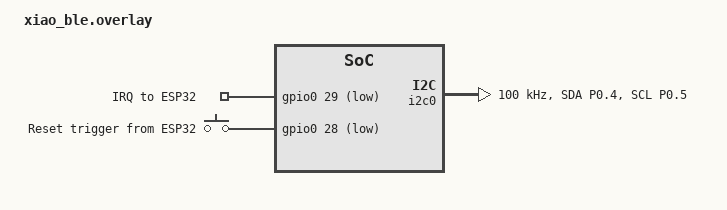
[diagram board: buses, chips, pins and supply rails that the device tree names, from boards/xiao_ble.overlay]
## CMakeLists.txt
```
cmake_minimum_required(VERSION 3.20.0)
find_package(Zephyr REQUIRED HINTS $ENV{ZEPHYR_BASE})
project(xiao_ble)

target_sources(app PRIVATE
    src/main.c
    src/i2c_target.c
    src/event_queue.c
    src/ble_central.c
    src/gatt_client.c
)
```

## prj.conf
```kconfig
# Phase 2: I2C Target + BLE Central (Scanning)

# I2C Target Mode
CONFIG_I2C=y
CONFIG_I2C_TARGET=y
CONFIG_I2C_TARGET_BUFFER_MODE=y

# GPIO (IRQ output + RST input)
CONFIG_GPIO=y

# BLE Central (scanning, future: connections)
CONFIG_BT=y
CONFIG_BT_CENTRAL=y
CONFIG_BT_OBSERVER=y
CONFIG_BT_GATT_CLIENT=y
CONFIG_BT_MAX_CONN=5
CONFIG_BT_MAX_PAIRED=5
CONFIG_BT_DEVICE_NAME="XIAO-BLE-Bridge"

# BLE Security (needed for Phase 3+)
CONFIG_BT_SMP=y
CONFIG_BT_BONDABLE=y
CONFIG_BT_SETTINGS=y
CONFIG_SETTINGS=y
CONFIG_FLASH=y
CONFIG_FLASH_MAP=y
CONFIG_NVS=y

# Persistent auto-reconnect: background connect to bonded bulbs via the
# controller filter accept list (Phase 5).
CONFIG_BT_FILTER_ACCEPT_LIST=y

# Connection timeout (Hue bulbs advertise slowly, need >3s default)
CONFIG_BT_CREATE_CONN_TIMEOUT=10

# Logging
CONFIG_LOG=y
CONFIG_LOG_DEFAULT_LEVEL=3
CONFIG_BT_LOG_LEVEL_WRN=y

# Watchdog (reboot if no PING in 30s)
CONFIG_WATCHDOG=y
CONFIG_WDT_DISABLE_AT_BOOT=n

# System
CONFIG_REBOOT=y
CONFIG_MAIN_STACK_SIZE=4096
```

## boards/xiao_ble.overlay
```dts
/*
 * Device tree overlay for XIAO nRF52840 BLE offload firmware.
 *
 * Pin assignments:
 *   D4 (P0.04) = SDA  (I2C target)
 *   D5 (P0.05) = SCL  (I2C target)
 *   D3 (P0.29) = IRQ  output to ESP32 (active LOW)
 *   D2 (P0.28) = RST  input from ESP32 (falling edge triggers reboot)
 */

/ {
    aliases {
        i2c-target = &i2c0;
    };

    gpio_pins {
        compatible = "gpio-keys";

        irq_pin: irq_pin {
            gpios = <&gpio0 29 GPIO_ACTIVE_LOW>;
            label = "IRQ to ESP32";
        };

        rst_pin: rst_pin {
            gpios = <&gpio0 28 (GPIO_PULL_UP | GPIO_ACTIVE_LOW)>;
            label = "Reset trigger from ESP32";
        };
    };
};

&i2c0 {
    compatible = "nordic,nrf-twis";
    status = "okay";
    pinctrl-0 = <&i2c0_default>;
    pinctrl-names = "default";
    clock-frequency = <I2C_BITRATE_STANDARD>;
};

&pinctrl {
    i2c0_default: i2c0_default {
        group1 {
            psels = <NRF_PSEL(TWIS_SDA, 0, 4)>,
                    <NRF_PSEL(TWIS_SCL, 0, 5)>;
        };
    };
};
```

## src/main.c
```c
/**
 * main.c — XIAO nRF52840 BLE offload firmware (Phase 1: I2C + PING/PONG)
 *
 * Initializes:
 *   - I2C target interface (address 0x08)
 *   - Event queue with IRQ signalling (D3 / P0.29)
 *   - Reset trigger input (D2 / P0.28)
 *   - Software watchdog (reboots if no PING in 30s)
 *
 * Queues a READY event on boot so the ESP32 knows we're alive.
 */

#include <zephyr/kernel.h>
#include <zephyr/drivers/gpio.h>
#include <zephyr/sys/reboot.h>
#include <zephyr/logging/log.h>

#include "i2c_target.h"
#include "event_queue.h"
#include "ble_central.h"

LOG_MODULE_REGISTER(main, LOG_LEVEL_INF);

/* Red LED (P0.26) — used as heartbeat indicator */
#define LED_NODE DT_ALIAS(led0)
static const struct gpio_dt_spec led = GPIO_DT_SPEC_GET(LED_NODE, gpios);

/* Reset input pin — D2 is P0.28 on XIAO nRF52840 */
#define RST_GPIO_NODE DT_NODELABEL(gpio0)
#define RST_PIN       28

/* Watchdog timeout: reboot if no PING for this many seconds */
#define WDT_TIMEOUT_SEC 30

static const struct device *rst_gpio_dev;
static struct gpio_callback rst_cb_data;

/* Reset pin interrupt callback */
static void rst_pin_handler(const struct device *dev,
                            struct gpio_callback *cb,
                            uint32_t pins)
{
    LOG_WRN("Reset triggered by ESP32 via D2");
    k_msleep(5);  /* brief delay for signal stability */
    sys_reboot(SYS_REBOOT_COLD);
}

static int init_reset_pin(void)
{
    rst_gpio_dev = DEVICE_DT_GET(RST_GPIO_NODE);
    if (!device_is_ready(rst_gpio_dev)) {
        LOG_ERR("RST GPIO device not ready");
        return -ENODEV;
    }

    int ret = gpio_pin_configure(rst_gpio_dev, RST_PIN,
                                  GPIO_INPUT | GPIO_PULL_UP);
    if (ret < 0) {
        LOG_ERR("Failed to configure RST pin: %d", ret);
        return ret;
    }

    ret = gpio_pin_interrupt_configure(rst_gpio_dev, RST_PIN,
                                        GPIO_INT_EDGE_TO_ACTIVE);
    if (ret < 0) {
        LOG_ERR("Failed to configure RST interrupt: %d", ret);
        return ret;
    }

    gpio_init_callback(&rst_cb_data, rst_pin_handler, BIT(RST_PIN));
    gpio_add_callback(rst_gpio_dev, &rst_cb_data);

    LOG_INF("Reset pin (D2/P0.%d) ready", RST_PIN);
    return 0;
}

/* Declared in i2c_target.c */
extern bool i2c_target_check_ping(void);

int main(void)
{
    int ret;

    LOG_INF("XIAO BLE offload firmware v%d starting", FIRMWARE_VERSION);

    /* Configure heartbeat LED */
    if (gpio_is_ready_dt(&led)) {
        gpio_pin_configure_dt(&led, GPIO_OUTPUT_ACTIVE);
    }

    /* Initialize event queue (includes IRQ GPIO setup) */
    ret = event_queue_init();
    if (ret < 0) {
        LOG_ERR("Event queue init failed: %d", ret);
        return ret;
    }

    /* Initialize I2C target */
    ret = i2c_target_init();
    if (ret < 0) {
        LOG_ERR("I2C target init failed: %d", ret);
        return ret;
    }

    /* Initialize BLE stack */
    ret = ble_central_init();
    if (ret < 0) {
        LOG_ERR("BLE init failed: %d", ret);
        return ret;
    }

    /* Initialize reset input pin */
    ret = init_reset_pin();
    if (ret < 0) {
        LOG_WRN("Reset pin init failed (non-fatal): %d", ret);
    }

    /* Begin persistent auto-reconnect to all bonded bulbs (Phase 5). Bonds
     * were loaded by ble_central_init(); this arms background connection so
     * bulbs stay reachable without an explicit command. */
    ble_central_autoconnect_start();

    /* Queue READY event — ESP32 will see IRQ go LOW */
    event_queue_push_simple(EVT_READY);
    LOG_INF("READY event queued, waiting for ESP32");

    /*
     * Main loop: software watchdog.
     * If we don't receive a PING within WDT_TIMEOUT_SEC, reboot.
     */
    int64_t last_ping_time = k_uptime_get();

    while (1) {
        k_msleep(1000);  /* check every second */

        /* Toggle LED as heartbeat */
        if (gpio_is_ready_dt(&led)) {
            gpio_pin_toggle_dt(&led);
        }

        if (i2c_target_check_ping()) {
            last_ping_time = k_uptime_get();
            LOG_DBG("PING received, watchdog fed");
        }

        int64_t elapsed_ms = k_uptime_get() - last_ping_time;
        if (elapsed_ms > (WDT_TIMEOUT_SEC * 1000)) {
            LOG_ERR("No PING for %d seconds, rebooting!", WDT_TIMEOUT_SEC);
            sys_reboot(SYS_REBOOT_COLD);
        }
    }

    return 0;
}
```

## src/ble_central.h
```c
#ifndef BLE_CENTRAL_H
#define BLE_CENTRAL_H

#include <stdint.h>
#include <stdbool.h>

/**
 * Initialize the BLE stack (must be called from main thread).
 * Returns 0 on success.
 */
int ble_central_init(void);

/*
 * Scanning
 */

/**
 * Start BLE scanning for the given duration (seconds).
 * Scan results are queued as EVT_SCAN_RESULT events.
 * EVT_SCAN_DONE is queued when duration expires or scan_stop() called.
 * Returns 0 on success.
 */
int ble_central_scan_start(uint8_t duration_sec);

/**
 * Stop an active scan immediately.
 * Queues EVT_SCAN_DONE.
 * Returns 0 on success, -EALREADY if not scanning.
 */
int ble_central_scan_stop(void);

/**
 * Returns true if a scan is currently active.
 */
bool ble_central_is_scanning(void);

/*
 * Connections
 */

/**
 * Connect to a BLE device by address.
 * addr: 6-byte BLE address (little-endian)
 * addr_type: 0 = public, 1 = random
 * Queues EVT_CONNECTED on success, EVT_CMD_ERROR on failure.
 * Returns 0 if connection attempt started.
 */
int ble_central_connect(const uint8_t *addr, uint8_t addr_type);

/**
 * Disconnect a connection by handle.
 * Queues EVT_DISCONNECTED.
 * Returns 0 on success.
 */
int ble_central_disconnect(uint16_t conn_handle);

/**
 * Initiate bonding (pairing + key storage) on a connection.
 * Requires an active connection. Queues EVT_BOND_COMPLETE.
 * Returns 0 if bonding started.
 */
int ble_central_bond(uint16_t conn_handle);

/**
 * Delete the stored bond (LTK) for a peer address.
 * addr: 6-byte BLE address (little-endian)
 * addr_type: 0 = public, 1 = random
 * No connection required; clears the key from settings/NVS.
 * Returns 0 on success (or if no bond existed).
 */
int ble_central_unpair(const uint8_t *addr, uint8_t addr_type);

/**
 * Delete all stored bonds.
 * Returns 0 on success.
 */
int ble_central_unpair_all(void);

/**
 * Get connection handle for an address. Returns -1 if not connected.
 */
int ble_central_get_handle(const uint8_t *addr);

/**
 * Get number of active connections.
 */
uint8_t ble_central_connection_count(void);

/**
 * Re-announce all currently active connections by queuing EVT_CONNECTED for
 * each (plus EVT_ENC_CHANGE for those already encrypted). Lets the ESP32
 * rebuild its view of live links after an independent reboot, since the nRF
 * holds connections across ESP32 restarts.
 */
void ble_central_report_connections(void);

/**
 * Get the bt_conn pointer for a connection handle.
 * Returns NULL if handle is invalid or not connected.
 * Used by gatt_client to issue GATT operations.
 */
struct bt_conn *ble_central_get_conn(uint16_t conn_handle);

/**
 * Map a bt_conn pointer back to our connection handle index.
 * Returns 0xFFFF if not found.
 */
uint16_t ble_central_conn_to_handle(struct bt_conn *conn);

/*
 * Persistent auto-reconnect (Phase 5)
 */

/**
 * Populate the filter accept list from stored bonds and begin background
 * auto-connection to every bonded bulb. Bonded devices are then kept
 * persistently connected (and re-encrypted) without any command from the
 * ESP32, reconnecting automatically whenever they advertise.
 *
 * Call once after ble_central_init(). Safe to call again to refresh the
 * accept list after bonds change. Returns 0 on success.
 */
int ble_central_autoconnect_start(void);

#endif /* BLE_CENTRAL_H */
```

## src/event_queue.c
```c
/**
 * event_queue.c — FIFO event queue with IRQ GPIO signalling.
 *
 * Events are queued by BLE callbacks (or PING handler in Phase 1)
 * and drained by the ESP32 reading REG_EVENT via I2C.
 *
 * IRQ pin (D3 / P0.29): HIGH = idle, LOW = events pending.
 */

#include <zephyr/kernel.h>
#include <zephyr/drivers/gpio.h>
#include <zephyr/logging/log.h>
#include <string.h>

#include "event_queue.h"

LOG_MODULE_REGISTER(event_queue, LOG_LEVEL_INF);

/* IRQ GPIO — D3 is P0.29 on XIAO nRF52840 */
#define IRQ_NODE DT_NODELABEL(gpio0)
#define IRQ_PIN  29

static const struct device *gpio_dev;

/* Circular buffer */
static struct event_entry queue[EVENT_QUEUE_SIZE];
static uint8_t head;  /* next read position */
static uint8_t tail;  /* next write position */
static uint8_t count;

static struct k_spinlock lock;

static void irq_pin_set(bool events_pending)
{
    if (gpio_dev) {
        /* Active LOW: events pending = pin LOW */
        gpio_pin_set(gpio_dev, IRQ_PIN, events_pending ? 0 : 1);
    }
}

int event_queue_init(void)
{
    gpio_dev = DEVICE_DT_GET(IRQ_NODE);
    if (!device_is_ready(gpio_dev)) {
        LOG_ERR("GPIO device not ready");
        return -ENODEV;
    }

    int ret = gpio_pin_configure(gpio_dev, IRQ_PIN,
                                  GPIO_OUTPUT_HIGH);  /* idle = HIGH */
    if (ret < 0) {
        LOG_ERR("Failed to configure IRQ pin: %d", ret);
        return ret;
    }

    head = 0;
    tail = 0;
    count = 0;

    LOG_INF("Event queue initialized (IRQ on P0.%d)", IRQ_PIN);
    return 0;
}

int event_queue_push(uint8_t type, const uint8_t *payload, uint8_t len)
{
    if (len > EVENT_MAX_PAYLOAD) {
        len = EVENT_MAX_PAYLOAD;
    }

    k_spinlock_key_t key = k_spin_lock(&lock);

    if (count >= EVENT_QUEUE_SIZE) {
        k_spin_unlock(&lock, key);
        LOG_WRN("Event queue full, dropping event 0x%02x", type);
        return -ENOMEM;
    }

    struct event_entry *entry = &queue[tail];
    entry->type = type;
    entry->payload_len = len;
    if (payload && len > 0) {
        memcpy(entry->payload, payload, len);
    }

    tail = (tail + 1) % EVENT_QUEUE_SIZE;
    count++;

    /* Assert IRQ if this is the first event */
    if (count == 1) {
        irq_pin_set(true);
    }

    k_spin_unlock(&lock, key);

    LOG_DBG("Pushed event 0x%02x (len=%u, pending=%u)", type, len, count);
    return 0;
}

const struct event_entry *event_queue_peek(void)
{
    k_spinlock_key_t key = k_spin_lock(&lock);

    const struct event_entry *entry = NULL;
    if (count > 0) {
        entry = &queue[head];
    }

    k_spin_unlock(&lock, key);
    return entry;
}

const struct event_entry *event_queue_pop(void)
{
    k_spinlock_key_t key = k_spin_lock(&lock);

    if (count == 0) {
        k_spin_unlock(&lock, key);
        return NULL;
    }

    const struct event_entry *entry = &queue[head];
    head = (head + 1) % EVENT_QUEUE_SIZE;
    count--;

    /* Release IRQ if queue is now empty */
    if (count == 0) {
        irq_pin_set(false);
    }

    k_spin_unlock(&lock, key);

    LOG_DBG("Popped event 0x%02x (remaining=%u)", entry->type, count);
    return entry;
}

uint8_t event_queue_count(void)
{
    k_spinlock_key_t key = k_spin_lock(&lock);
    uint8_t n = count;
    k_spin_unlock(&lock, key);
    return n;
}
```

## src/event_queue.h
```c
#ifndef EVENT_QUEUE_H
#define EVENT_QUEUE_H

#include <stdint.h>
#include <stdbool.h>

/* Maximum events in the FIFO queue */
#define EVENT_QUEUE_SIZE 32

/* Maximum event payload size */
#define EVENT_MAX_PAYLOAD 60

/* Single event entry */
struct event_entry {
    uint8_t type;
    uint8_t payload_len;
    uint8_t payload[EVENT_MAX_PAYLOAD];
};

/**
 * Initialize the event queue and IRQ GPIO pin.
 * Returns 0 on success.
 */
int event_queue_init(void);

/**
 * Push an event onto the queue. Asserts IRQ LOW if queue was empty.
 * Returns 0 on success, -ENOMEM if queue full.
 */
int event_queue_push(uint8_t type, const uint8_t *payload, uint8_t len);

/**
 * Peek at the next event (for REG_EVENT_LEN reads).
 * Returns NULL if queue is empty.
 */
const struct event_entry *event_queue_peek(void);

/**
 * Pop the next event from the queue.
 * Releases IRQ HIGH if queue becomes empty.
 * Returns NULL if queue is empty.
 */
const struct event_entry *event_queue_pop(void);

/**
 * Get the number of pending events.
 */
uint8_t event_queue_count(void);

/**
 * Push a simple event with no payload.
 */
static inline int event_queue_push_simple(uint8_t type)
{
    return event_queue_push(type, NULL, 0);
}

#endif /* EVENT_QUEUE_H */
```

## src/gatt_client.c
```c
/**
 * gatt_client.c — GATT client operations (Phase 4).
 *
 * Provides service/characteristic discovery, read, write, and subscribe.
 * Results are queued as events for the ESP32 to drain via I2C.
 */

#include <zephyr/kernel.h>
#include <zephyr/bluetooth/bluetooth.h>
#include <zephyr/bluetooth/gatt.h>
#include <zephyr/bluetooth/uuid.h>
#include <zephyr/logging/log.h>
#include <string.h>

#include "gatt_client.h"
#include "ble_central.h"
#include "i2c_target.h"
#include "event_queue.h"

LOG_MODULE_REGISTER(gatt_client, LOG_LEVEL_INF);

/*
 * Discovery state — only one discovery at a time.
 */
static uint16_t discover_conn_handle;
static struct bt_gatt_discover_params discover_params;
static struct bt_uuid_16 discover_uuid;

/*
 * Read state
 */
static struct bt_gatt_read_params read_params;
static uint16_t read_conn_handle;
static uint16_t read_attr_handle;

/*
 * Write state
 */
static uint16_t write_conn_handle;
static uint16_t write_attr_handle;

/*
 * Subscribe state
 */
static struct bt_gatt_subscribe_params subscribe_params;

/* ================================================================
 * GATT Discovery
 * ================================================================ */

static uint8_t discover_cb(struct bt_conn *conn,
                           const struct bt_gatt_attr *attr,
                           struct bt_gatt_discover_params *params)
{
    if (!attr) {
        LOG_INF("Discovery complete [%u]", discover_conn_handle);
        /* Signal discovery done with a zero-length characteristic event */
        uint8_t payload[4];
        payload[0] = discover_conn_handle & 0xFF;
        payload[1] = (discover_conn_handle >> 8) & 0xFF;
        payload[2] = 0;  /* handle = 0 means "done" */
        payload[3] = 0;
        event_queue_push(EVT_GATT_SERVICES, payload, 4);
        return BT_GATT_ITER_STOP;
    }

    struct bt_gatt_chrc *chrc = (struct bt_gatt_chrc *)attr->user_data;

    /*
     * Build event payload:
     *   [conn_handle:2, value_handle:2, properties:1, uuid_len:1, uuid...]
     *
     * For 128-bit UUIDs: uuid_len = 16
     * For 16-bit UUIDs: uuid_len = 2
     */
    uint8_t payload[6 + 16];  /* max: 2+2+1+1+16 = 22 bytes */
    uint8_t uuid_len;

    payload[0] = discover_conn_handle & 0xFF;
    payload[1] = (discover_conn_handle >> 8) & 0xFF;
    payload[2] = chrc->value_handle & 0xFF;
    payload[3] = (chrc->value_handle >> 8) & 0xFF;
    payload[4] = chrc->properties;

    if (chrc->uuid->type == BT_UUID_TYPE_128) {
        uuid_len = 16;
        /* BT_UUID_128 stores bytes in little-endian order */
        memcpy(&payload[6], BT_UUID_128(chrc->uuid)->val, 16);
    } else {
        uuid_len = 2;
        payload[6] = BT_UUID_16(chrc->uuid)->val & 0xFF;
        payload[7] = (BT_UUID_16(chrc->uuid)->val >> 8) & 0xFF;
    }
    payload[5] = uuid_len;

    event_queue_push(EVT_GATT_SERVICES, payload, 6 + uuid_len);

    LOG_DBG("  Char handle=0x%04x props=0x%02x uuid_len=%u",
            chrc->value_handle, chrc->properties, uuid_len);

    return BT_GATT_ITER_CONTINUE;
}

int gatt_client_discover(uint16_t conn_handle)
{
    struct bt_conn *conn = ble_central_get_conn(conn_handle);
    if (!conn) {
        LOG_ERR("Discover: invalid handle %u", conn_handle);
        return -EINVAL;
    }

    discover_conn_handle = conn_handle;

    /* Discover all characteristics (no UUID filter) */
    discover_params.uuid = NULL;
    discover_params.func = discover_cb;
    discover_params.start_handle = BT_ATT_FIRST_ATTRIBUTE_HANDLE;
    discover_params.end_handle = BT_ATT_LAST_ATTRIBUTE_HANDLE;
    discover_params.type = BT_GATT_DISCOVER_CHARACTERISTIC;

    int err = bt_gatt_discover(conn, &discover_params);
    if (err) {
        LOG_ERR("Discover start failed: %d", err);
    } else {
        LOG_INF("GATT discovery started [%u]", conn_handle);
    }

    return err;
}

/* ================================================================
 * GATT Read
 * ================================================================ */

static uint8_t read_cb(struct bt_conn *conn, uint8_t err,
                       struct bt_gatt_read_params *params,
                       const void *data, uint16_t length)
{
    if (err) {
        LOG_ERR("Read failed [%u] handle=0x%04x: err=%u",
                read_conn_handle, read_attr_handle, err);
        /* Queue error response */
        uint8_t payload[5];
        payload[0] = read_conn_handle & 0xFF;
        payload[1] = (read_conn_handle >> 8) & 0xFF;
        payload[2] = read_attr_handle & 0xFF;
        payload[3] = (read_attr_handle >> 8) & 0xFF;
        payload[4] = err;
        event_queue_push(EVT_GATT_READ_RSP, payload, 5);
        return BT_GATT_ITER_STOP;
    }

    if (!data || length == 0) {
        /* End of read — for single reads this shouldn't happen with data=NULL
         * unless there's nothing to read. Queue empty response. */
        if (length == 0) {
            uint8_t payload[4];
            payload[0] = read_conn_handle & 0xFF;
            payload[1] = (read_conn_handle >> 8) & 0xFF;
            payload[2] = read_attr_handle & 0xFF;
            payload[3] = (read_attr_handle >> 8) & 0xFF;
            event_queue_push(EVT_GATT_READ_RSP, payload, 4);
        }
        return BT_GATT_ITER_STOP;
    }

    /* Queue read response: [conn_handle:2, attr_handle:2, data...] */
    uint8_t payload[4 + 56];  /* max data that fits in event payload */
    uint16_t copy_len = (length > 56) ? 56 : length;

    payload[0] = read_conn_handle & 0xFF;
    payload[1] = (read_conn_handle >> 8) & 0xFF;
    payload[2] = read_attr_handle & 0xFF;
    payload[3] = (read_attr_handle >> 8) & 0xFF;
    memcpy(&payload[4], data, copy_len);

    event_queue_push(EVT_GATT_READ_RSP, payload, 4 + copy_len);

    LOG_INF("Read response [%u] handle=0x%04x len=%u",
            read_conn_handle, read_attr_handle, length);

    return BT_GATT_ITER_STOP;
}

int gatt_client_read(uint16_t conn_handle, uint16_t attr_handle)
{
    struct bt_conn *conn = ble_central_get_conn(conn_handle);
    if (!conn) {
        LOG_ERR("Read: invalid conn handle %u", conn_handle);
        return -EINVAL;
    }

    read_conn_handle = conn_handle;
    read_attr_handle = attr_handle;

    read_params.func = read_cb;
    read_params.handle_count = 1;
    read_params.single.handle = attr_handle;
    read_params.single.offset = 0;

    int err = bt_gatt_read(conn, &read_params);
    if (err) {
        LOG_ERR("Read start failed: %d", err);
    } else {
        LOG_INF("GATT read started [%u] handle=0x%04x", conn_handle, attr_handle);
    }

    return err;
}

/* ================================================================
 * GATT Write (with response)
 * ================================================================ */

static void write_cb(struct bt_conn *conn, uint8_t err,
                     struct bt_gatt_write_params *params)
{
    /* Queue write response: [conn_handle:2, attr_handle:2, status:1] */
    uint8_t payload[5];
    payload[0] = write_conn_handle & 0xFF;
    payload[1] = (write_conn_handle >> 8) & 0xFF;
    payload[2] = write_attr_handle & 0xFF;
    payload[3] = (write_attr_handle >> 8) & 0xFF;
    payload[4] = err;

    event_queue_push(EVT_GATT_WRITE_RSP, payload, 5);

    if (err) {
        LOG_ERR("Write failed [%u] handle=0x%04x: err=%u",
                write_conn_handle, write_attr_handle, err);
    } else {
        LOG_INF("Write done [%u] handle=0x%04x", write_conn_handle, write_attr_handle);
    }
}

/* Static buffer to hold write data (persists until callback fires) */
static uint8_t write_data_buf[56];
static struct bt_gatt_write_params write_params;

int gatt_client_write(uint16_t conn_handle, uint16_t attr_handle,
                      const uint8_t *data, uint16_t len)
{
    struct bt_conn *conn = ble_central_get_conn(conn_handle);
    if (!conn) {
        LOG_ERR("Write: invalid conn handle %u", conn_handle);
        return -EINVAL;
    }

    if (len > sizeof(write_data_buf)) {
        LOG_ERR("Write data too large: %u", len);
        return -EINVAL;
    }

    write_conn_handle = conn_handle;
    write_attr_handle = attr_handle;

    /* Copy data to static buffer (must persist until callback) */
    memcpy(write_data_buf, data, len);

    write_params.func = write_cb;
    write_params.handle = attr_handle;
    write_params.offset = 0;
    write_params.data = write_data_buf;
    write_params.length = len;

    int err = bt_gatt_write(conn, &write_params);
    if (err) {
        LOG_ERR("Write start failed: %d", err);
    } else {
        LOG_INF("GATT write started [%u] handle=0x%04x len=%u",
                conn_handle, attr_handle, len);
    }

    return err;
}

/* ================================================================
 * GATT Write Without Response
 * ================================================================ */

int gatt_client_write_nr(uint16_t conn_handle, uint16_t attr_handle,
                         const uint8_t *data, uint16_t len)
{
    struct bt_conn *conn = ble_central_get_conn(conn_handle);
    if (!conn) {
        LOG_ERR("Write NR: invalid conn handle %u", conn_handle);
        return -EINVAL;
    }

    int err = bt_gatt_write_without_response(conn, attr_handle, data, len, false);
    if (err) {
        LOG_ERR("Write NR failed: %d", err);
    } else {
        LOG_DBG("Write NR done [%u] handle=0x%04x len=%u",
                conn_handle, attr_handle, len);
    }

    return err;
}

/* ================================================================
 * GATT Subscribe (Notifications/Indications)
 * ================================================================ */

static uint8_t notify_cb(struct bt_conn *conn,
                         struct bt_gatt_subscribe_params *params,
                         const void *data, uint16_t length)
{
    if (!data) {
        /* Subscription removed */
        LOG_INF("Subscription removed");
        return BT_GATT_ITER_STOP;
    }

    /* Find connection handle */
    uint16_t ch = ble_central_conn_to_handle(conn);

    /* Queue notification event: [conn_handle:2, attr_handle:2, data...] */
    uint8_t payload[4 + 56];
    uint16_t copy_len = (length > 56) ? 56 : length;

    payload[0] = ch & 0xFF;
    payload[1] = (ch >> 8) & 0xFF;
    payload[2] = params->value_handle & 0xFF;
    payload[3] = (params->value_handle >> 8) & 0xFF;
    memcpy(&payload[4], data, copy_len);

    event_queue_push(EVT_GATT_NOTIFY, payload, 4 + copy_len);

    LOG_DBG("Notify [%u] handle=0x%04x len=%u", ch, params->value_handle, length);

    return BT_GATT_ITER_CONTINUE;
}

int gatt_client_subscribe(uint16_t conn_handle, uint16_t attr_handle,
                          uint8_t type)
{
    struct bt_conn *conn = ble_central_get_conn(conn_handle);
    if (!conn) {
        LOG_ERR("Subscribe: invalid conn handle %u", conn_handle);
        return -EINVAL;
    }

    subscribe_params.notify = notify_cb;
    subscribe_params.value_handle = attr_handle;
    /* CCC handle is typically value_handle + 1 */
    subscribe_params.ccc_handle = attr_handle + 1;
    subscribe_params.value = (type == 2) ? BT_GATT_CCC_INDICATE : BT_GATT_CCC_NOTIFY;

    int err = bt_gatt_subscribe(conn, &subscribe_params);
    if (err) {
        LOG_ERR("Subscribe failed: %d", err);
    } else {
        LOG_INF("Subscribed [%u] handle=0x%04x type=%u",
                conn_handle, attr_handle, type);
    }

    return err;
}
```

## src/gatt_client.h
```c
#ifndef GATT_CLIENT_H
#define GATT_CLIENT_H

#include <stdint.h>

/**
 * Discover all services and characteristics on a connection.
 * Results are queued as EVT_GATT_SERVICES events, one per characteristic:
 *   [conn_handle:2, char_handle:2, properties:1, uuid_len:1, uuid:uuid_len]
 *
 * Returns 0 if discovery started.
 */
int gatt_client_discover(uint16_t conn_handle);

/**
 * Read a characteristic by its ATT value handle.
 * Result queued as EVT_GATT_READ_RSP:
 *   [conn_handle:2, attr_handle:2, data...]
 *
 * Returns 0 if read started.
 */
int gatt_client_read(uint16_t conn_handle, uint16_t attr_handle);

/**
 * Write a characteristic (with response) by ATT value handle.
 * Result queued as EVT_GATT_WRITE_RSP:
 *   [conn_handle:2, attr_handle:2, status:1]
 *
 * Returns 0 if write started.
 */
int gatt_client_write(uint16_t conn_handle, uint16_t attr_handle,
                      const uint8_t *data, uint16_t len);

/**
 * Write without response (no acknowledgment from remote).
 * No event is queued on success.
 * Returns 0 on success.
 */
int gatt_client_write_nr(uint16_t conn_handle, uint16_t attr_handle,
                         const uint8_t *data, uint16_t len);

/**
 * Subscribe to notifications/indications on a characteristic.
 * type: 1 = notify, 2 = indicate
 * Returns 0 if subscribe started.
 */
int gatt_client_subscribe(uint16_t conn_handle, uint16_t attr_handle,
                          uint8_t type);

#endif /* GATT_CLIENT_H */
```

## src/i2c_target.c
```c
/**
 * i2c_target.c — Register-based I2C target handler (buffer mode).
 *
 * The ESP32-S3 (controller) communicates with this XIAO nRF52840 (target)
 * using a simple register interface:
 *
 *   Write REG_CMD:       receive a command (first byte = cmd ID)
 *   Read  REG_STATUS:    return [version, events_pending]
 *   Read  REG_CMD_STATUS: return [last_seq, result]
 *   Read  REG_EVENT_LEN: return [event_type, payload_len] of next event
 *   Read  REG_EVENT:     return next event payload (and pop from queue)
 *
 * Uses Zephyr's I2C target BUFFER MODE API (required by nRF TWIS driver).
 * The TWIS DMA receives/transmits entire buffers, not byte-by-byte.
 */

#include <zephyr/kernel.h>
#include <zephyr/drivers/i2c.h>
#include <zephyr/sys/reboot.h>
#include <zephyr/logging/log.h>
#include <string.h>

#include "i2c_target.h"
#include "event_queue.h"
#include "ble_central.h"
#include "gatt_client.h"

LOG_MODULE_REGISTER(i2c_target, LOG_LEVEL_INF);

/* State */
static uint8_t current_reg;            /* register selected by last write */
static uint8_t last_cmd_seq;           /* sequence tracking */
static uint8_t last_cmd_result;        /* result of last command */
static volatile bool ping_received;    /* flag for watchdog feed */

/* Response buffer for reads */
static uint8_t resp_buf[MAX_PAYLOAD_SIZE + 4];
static uint32_t resp_len;

/*
 * Deferred command processing — BLE APIs require thread context,
 * but I2C target callbacks run in ISR context (nRF TWIS DMA).
 * We copy the command into a buffer and submit a work item.
 */
static uint8_t cmd_buf[MAX_PAYLOAD_SIZE];
static uint8_t cmd_buf_len;
static struct k_work cmd_work;

static void handle_command_isr(const uint8_t *data, uint8_t len);
static void cmd_work_handler(struct k_work *work);

/*
 * Buffer-mode I2C target callbacks (required by nRF TWIS DMA driver).
 */

/**
 * Called when the controller has finished writing data to us.
 * buf[0] = register address, buf[1..] = payload (if any).
 */
static void target_buf_write_received(struct i2c_target_config *config,
                                       uint8_t *buf, uint32_t len)
{
    if (len == 0) {
        return;
    }

    /* First byte is always the register address */
    current_reg = buf[0];

    /* If writing to REG_CMD with payload, process command */
    if (current_reg == REG_CMD && len > 1) {
        handle_command_isr(&buf[1], len - 1);
    }
}

/**
 * Called when the controller wants to read from us.
 * We fill resp_buf based on current_reg (set by prior write) and
 * provide the pointer and length.
 */
static int target_buf_read_requested(struct i2c_target_config *config,
                                      uint8_t **buf, uint32_t *buf_size)
{
    resp_len = 0;

    switch (current_reg) {
    case REG_STATUS:
        resp_buf[0] = FIRMWARE_VERSION;
        resp_buf[1] = event_queue_count();
        resp_len = 2;
        break;

    case REG_CMD_STATUS:
        resp_buf[0] = last_cmd_seq;
        resp_buf[1] = last_cmd_result;
        resp_len = 2;
        break;

    case REG_EVENT_LEN: {
        const struct event_entry *evt = event_queue_peek();
        if (evt) {
            resp_buf[0] = evt->type;
            resp_buf[1] = evt->payload_len;
        } else {
            resp_buf[0] = 0;
            resp_buf[1] = 0;
        }
        resp_len = 2;
        break;
    }

    case REG_EVENT: {
        const struct event_entry *evt = event_queue_pop();
        if (evt) {
            resp_buf[0] = evt->type;
            resp_buf[1] = evt->payload_len;
            if (evt->payload_len > 0) {
                memcpy(&resp_buf[2], evt->payload, evt->payload_len);
            }
            resp_len = 2 + evt->payload_len;
        } else {
            resp_buf[0] = 0;
            resp_buf[1] = 0;
            resp_len = 2;
        }
        break;
    }

    default:
        resp_buf[0] = 0xFF;  /* unknown register */
        resp_len = 1;
        break;
    }

    *buf = resp_buf;
    *buf_size = resp_len;
    return 0;
}

/* I2C target callback table (buffer mode) */
static const struct i2c_target_callbacks target_callbacks = {
    .buf_write_received = target_buf_write_received,
    .buf_read_requested = target_buf_read_requested,
};

static struct i2c_target_config target_config = {
    .address = XIAO_I2C_ADDR,
    .callbacks = &target_callbacks,
};

/*
 * Command handling — split into ISR-safe part and deferred (thread) part.
 *
 * ISR-safe commands (PING, RESET): handled immediately in callback context.
 * BLE commands (SCAN_START, etc.): deferred to system work queue (thread context).
 */
static void handle_command_isr(const uint8_t *data, uint8_t len)
{
    if (len == 0) {
        return;
    }

    uint8_t cmd_id = data[0];
    last_cmd_seq++;

    LOG_INF("CMD 0x%02x (len=%u)", cmd_id, len);

    switch (cmd_id) {
    case CMD_PING: {
        /* ISR-safe: just pushes to event queue.
         * Payload: [version, conn_count, uptime_sec (4B little-endian)]. */
        uint32_t uptime_sec = (uint32_t)(k_uptime_get() / 1000);
        uint8_t pong_payload[6] = {
            FIRMWARE_VERSION,
            ble_central_connection_count(),
            (uint8_t)(uptime_sec & 0xFF),
            (uint8_t)((uptime_sec >> 8) & 0xFF),
            (uint8_t)((uptime_sec >> 16) & 0xFF),
            (uint8_t)((uptime_sec >> 24) & 0xFF),
        };
        event_queue_push(EVT_PONG, pong_payload, sizeof(pong_payload));
        last_cmd_result = CMD_RESULT_OK;
        ping_received = true;
        break;
    }

    case CMD_RESET:
        last_cmd_result = CMD_RESULT_OK;
        k_msleep(10);
        sys_reboot(SYS_REBOOT_COLD);
        break;

    default:
        /* All other commands (BLE etc.) must run in thread context */
        if (len <= sizeof(cmd_buf)) {
            memcpy(cmd_buf, data, len);
            cmd_buf_len = len;
            k_work_submit(&cmd_work);
            last_cmd_result = CMD_RESULT_OK;
        } else {
            LOG_ERR("Command too large: %u", len);
            last_cmd_result = CMD_RESULT_ERROR;
        }
        break;
    }
}

/**
 * Deferred command handler — runs in system work queue (thread context).
 * Safe to call BLE APIs here.
 */
static void cmd_work_handler(struct k_work *work)
{
    if (cmd_buf_len == 0) {
        return;
    }

    uint8_t cmd_id = cmd_buf[0];

    LOG_INF("Deferred CMD 0x%02x (len=%u)", cmd_id, cmd_buf_len);

    switch (cmd_id) {
    case CMD_SCAN_START: {
        uint8_t duration = (cmd_buf_len > 1) ? cmd_buf[1] : 10;
        int err = ble_central_scan_start(duration);
        if (err != 0) {
            LOG_ERR("Scan start failed: %d", err);
            last_cmd_result = CMD_RESULT_ERROR;
        }
        break;
    }

    case CMD_SCAN_STOP: {
        int err = ble_central_scan_stop();
        if (err != 0) {
            last_cmd_result = CMD_RESULT_ERROR;
        }
        break;
    }

    case CMD_CONNECT: {
        /* Payload: [addr 6B, addr_type 1B] */
        if (cmd_buf_len < 8) {
            LOG_ERR("CONNECT: payload too short (%u)", cmd_buf_len);
            last_cmd_result = CMD_RESULT_ERROR;
            break;
        }
        int err = ble_central_connect(&cmd_buf[1], cmd_buf[7]);
        if (err != 0) {
            LOG_ERR("Connect failed: %d", err);
            last_cmd_result = CMD_RESULT_ERROR;
        }
        break;
    }

    case CMD_DISCONNECT: {
        /* Payload: [handle_lo, handle_hi] */
        if (cmd_buf_len < 3) {
            LOG_ERR("DISCONNECT: payload too short");
            last_cmd_result = CMD_RESULT_ERROR;
            break;
        }
        uint16_t handle = cmd_buf[1] | (cmd_buf[2] << 8);
        int err = ble_central_disconnect(handle);
        if (err != 0) {
            LOG_ERR("Disconnect failed: %d", err);
            last_cmd_result = CMD_RESULT_ERROR;
        }
        break;
    }

    case CMD_BOND: {
        /* Payload: [handle_lo, handle_hi] */
        if (cmd_buf_len < 3) {
            LOG_ERR("BOND: payload too short");
            last_cmd_result = CMD_RESULT_ERROR;
            break;
        }
        uint16_t handle = cmd_buf[1] | (cmd_buf[2] << 8);
        int err = ble_central_bond(handle);
        if (err != 0) {
            LOG_ERR("Bond failed: %d", err);
            last_cmd_result = CMD_RESULT_ERROR;
        }
        break;
    }

    case CMD_GATT_DISCOVER: {
        /* Payload: [handle_lo, handle_hi] */
        if (cmd_buf_len < 3) {
            LOG_ERR("GATT_DISCOVER: payload too short");
            last_cmd_result = CMD_RESULT_ERROR;
            break;
        }
        uint16_t handle = cmd_buf[1] | (cmd_buf[2] << 8);
        int err = gatt_client_discover(handle);
        if (err != 0) {
            LOG_ERR("GATT discover failed: %d", err);
            last_cmd_result = CMD_RESULT_ERROR;
        }
        break;
    }

    case CMD_GATT_READ: {
        /* Payload: [conn_handle_lo, conn_handle_hi, attr_handle_lo, attr_handle_hi] */
        if (cmd_buf_len < 5) {
            LOG_ERR("GATT_READ: payload too short");
            last_cmd_result = CMD_RESULT_ERROR;
            break;
        }
        uint16_t conn_h = cmd_buf[1] | (cmd_buf[2] << 8);
        uint16_t attr_h = cmd_buf[3] | (cmd_buf[4] << 8);
        int err = gatt_client_read(conn_h, attr_h);
        if (err != 0) {
            LOG_ERR("GATT read failed: %d", err);
            last_cmd_result = CMD_RESULT_ERROR;
        }
        break;
    }

    case CMD_GATT_WRITE: {
        /* Payload: [conn_handle:2, attr_handle:2, data...] */
        if (cmd_buf_len < 5) {
            LOG_ERR("GATT_WRITE: payload too short");
            last_cmd_result = CMD_RESULT_ERROR;
            break;
        }
        uint16_t conn_h = cmd_buf[1] | (cmd_buf[2] << 8);
        uint16_t attr_h = cmd_buf[3] | (cmd_buf[4] << 8);
        uint16_t data_len = cmd_buf_len - 5;
        int err = gatt_client_write(conn_h, attr_h, &cmd_buf[5], data_len);
        if (err != 0) {
            LOG_ERR("GATT write failed: %d", err);
            last_cmd_result = CMD_RESULT_ERROR;
        }
        break;
    }

    case CMD_GATT_WRITE_NR: {
        /* Payload: [conn_handle:2, attr_handle:2, data...] */
        if (cmd_buf_len < 5) {
            LOG_ERR("GATT_WRITE_NR: payload too short");
            last_cmd_result = CMD_RESULT_ERROR;
            break;
        }
        uint16_t conn_h = cmd_buf[1] | (cmd_buf[2] << 8);
        uint16_t attr_h = cmd_buf[3] | (cmd_buf[4] << 8);
        uint16_t data_len = cmd_buf_len - 5;
        int err = gatt_client_write_nr(conn_h, attr_h, &cmd_buf[5], data_len);
        if (err != 0) {
            LOG_ERR("GATT write NR failed: %d", err);
            last_cmd_result = CMD_RESULT_ERROR;
        }
        break;
    }

    case CMD_SUBSCRIBE: {
        /* Payload: [conn_handle:2, attr_handle:2, type:1] */
        if (cmd_buf_len < 6) {
            LOG_ERR("SUBSCRIBE: payload too short");
            last_cmd_result = CMD_RESULT_ERROR;
            break;
        }
        uint16_t conn_h = cmd_buf[1] | (cmd_buf[2] << 8);
        uint16_t attr_h = cmd_buf[3] | (cmd_buf[4] << 8);
        uint8_t type = cmd_buf[5];
        int err = gatt_client_subscribe(conn_h, attr_h, type);
        if (err != 0) {
            LOG_ERR("Subscribe failed: %d", err);
            last_cmd_result = CMD_RESULT_ERROR;
        }
        break;
    }

    case CMD_DELETE_BOND: {
        /* Payload: [addr 6B, addr_type 1B] */
        if (cmd_buf_len < 8) {
            LOG_ERR("DELETE_BOND: payload too short (%u)", cmd_buf_len);
            last_cmd_result = CMD_RESULT_ERROR;
            break;
        }
        int err = ble_central_unpair(&cmd_buf[1], cmd_buf[7]);
        if (err != 0) {
            LOG_ERR("Unpair failed: %d", err);
            last_cmd_result = CMD_RESULT_ERROR;
        }
        break;
    }

    case CMD_DELETE_ALL_BONDS: {
        int err = ble_central_unpair_all();
        if (err != 0) {
            LOG_ERR("Unpair all failed: %d", err);
            last_cmd_result = CMD_RESULT_ERROR;
        }
        break;
    }

    case CMD_LIST_CONNECTIONS:
        /* Re-announce live connections so the ESP32 can rebuild its view
         * after an independent reboot. */
        ble_central_report_connections();
        break;

    default:
        LOG_WRN("Unknown deferred command 0x%02x", cmd_id);
        last_cmd_result = CMD_RESULT_UNKNOWN;
        break;
    }
}

/*
 * Public API
 */

int i2c_target_init(void)
{
    const struct device *i2c_dev = DEVICE_DT_GET(DT_NODELABEL(i2c0));

    if (!device_is_ready(i2c_dev)) {
        LOG_ERR("I2C device not ready");
        return -ENODEV;
    }

    /* Initialize deferred command work item */
    k_work_init(&cmd_work, cmd_work_handler);

    int ret = i2c_target_register(i2c_dev, &target_config);
    if (ret < 0) {
        LOG_ERR("Failed to register I2C target: %d", ret);
        return ret;
    }

    LOG_INF("I2C target registered at address 0x%02x", XIAO_I2C_ADDR);
    return 0;
}

void i2c_target_ping_received(void)
{
    /* Reset the flag — called by main loop to check */
}

bool i2c_target_check_ping(void)
{
    bool got_ping = ping_received;
    ping_received = false;
    return got_ping;
}
```

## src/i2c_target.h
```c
#ifndef I2C_TARGET_H
#define I2C_TARGET_H

#include <stdint.h>
#include <stdbool.h>

/* I2C target address */
#define XIAO_I2C_ADDR 0x08

/* Register addresses */
#define REG_STATUS      0x00
#define REG_CMD         0x01
#define REG_CMD_STATUS  0x02
#define REG_EVENT       0x10
#define REG_EVENT_LEN   0x11

/* Command IDs */
#define CMD_PING             0x01
#define CMD_SCAN_START       0x02
#define CMD_SCAN_STOP        0x03
#define CMD_CONNECT          0x10
#define CMD_DISCONNECT       0x11
#define CMD_BOND             0x12
#define CMD_GATT_DISCOVER    0x13
#define CMD_GATT_READ        0x20
#define CMD_GATT_WRITE       0x21
#define CMD_GATT_WRITE_NR    0x22
#define CMD_SUBSCRIBE        0x23
#define CMD_GET_BONDS        0x30
#define CMD_DELETE_BOND      0x31
#define CMD_DELETE_ALL_BONDS 0x32
#define CMD_LIST_CONNECTIONS 0x33
#define CMD_RESET            0xFF

/* Event IDs */
#define EVT_PONG          0x81
#define EVT_READY         0x82
#define EVT_SCAN_RESULT   0x83
#define EVT_SCAN_DONE     0x84
#define EVT_CONNECTED     0x85
#define EVT_DISCONNECTED  0x86
#define EVT_BOND_COMPLETE 0x87
#define EVT_GATT_SERVICES 0x88
#define EVT_GATT_READ_RSP 0x89
#define EVT_GATT_WRITE_RSP 0x8A
#define EVT_GATT_NOTIFY   0x8B
#define EVT_ENC_CHANGE    0x8C
#define EVT_CMD_ERROR     0xFE

/* CMD_STATUS result codes */
#define CMD_RESULT_OK       0x00
#define CMD_RESULT_UNKNOWN  0x01
#define CMD_RESULT_BUSY     0x02
#define CMD_RESULT_ERROR    0x03

/* Max payload per I2C transaction */
#define MAX_PAYLOAD_SIZE 62

/* Firmware version (Phase 1) */
#define FIRMWARE_VERSION 0x01

/**
 * Initialize the I2C target interface.
 * Returns 0 on success.
 */
int i2c_target_init(void);

/**
 * Called when the watchdog is fed (PING received).
 */
void i2c_target_ping_received(void);

/**
 * Get the last command sequence number.
 */
uint8_t i2c_target_last_seq(void);

#endif /* I2C_TARGET_H */
```
